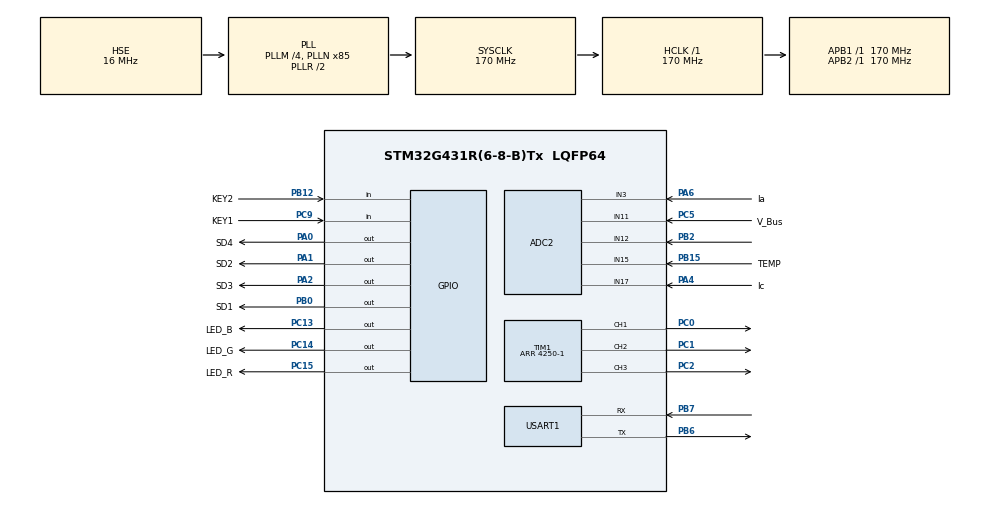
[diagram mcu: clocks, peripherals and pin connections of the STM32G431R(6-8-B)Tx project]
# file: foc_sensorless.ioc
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ADC2.Channel-0\#ChannelRegularConversion=ADC_CHANNEL_11
ADC2.Channel-1\#ChannelRegularConversion=ADC_CHANNEL_12
ADC2.Channel-2\#ChannelRegularConversion=ADC_CHANNEL_15
ADC2.ContinuousConvMode=DISABLE
ADC2.DMAContinuousRequests=ENABLE
ADC2.EnableInjectedConversion=ENABLE
ADC2.ExternalTrigConv=ADC_SOFTWARE_START
ADC2.ExternalTrigInjecConv=ADC_EXTERNALTRIGINJEC_T1_TRGO
ADC2.ExternalTrigInjecConvEdge=ADC_EXTERNALTRIGINJECCONV_EDGE_FALLING
ADC2.InjNumberOfConversion=2
ADC2.InjectedChannel-3\#ChannelInjectedConversion=ADC_CHANNEL_3
ADC2.InjectedChannel-4\#ChannelInjectedConversion=ADC_CHANNEL_17
ADC2.InjectedOffsetNumber-3\#ChannelInjectedConversion=ADC_OFFSET_NONE
ADC2.InjectedOffsetNumber-4\#ChannelInjectedConversion=ADC_OFFSET_NONE
ADC2.InjectedRank-3\#ChannelInjectedConversion=1
ADC2.InjectedRank-4\#ChannelInjectedConversion=2
ADC2.InjectedSamplingTime-3\#ChannelInjectedConversion=ADC_SAMPLETIME_2CYCLES_5
ADC2.InjectedSamplingTime-4\#ChannelInjectedConversion=ADC_SAMPLETIME_2CYCLES_5
ADC2.LowPowerAutoWait=DISABLE
ADC2.NbrOfConversion=3
ADC2.NbrOfConversionFlag=1
ADC2.OffsetNumber-0\#ChannelRegularConversion=ADC_OFFSET_NONE
ADC2.OffsetNumber-1\#ChannelRegularConversion=ADC_OFFSET_NONE
ADC2.OffsetNumber-2\#ChannelRegularConversion=ADC_OFFSET_NONE
ADC2.Rank-0\#ChannelRegularConversion=1
ADC2.Rank-1\#ChannelRegularConversion=2
ADC2.Rank-2\#ChannelRegularConversion=3
ADC2.Rank1_Channel=ADC_CHANNEL_3
ADC2.Rank2_Channel=ADC_CHANNEL_17
ADC2.SamplingTime-0\#ChannelRegularConversion=ADC_SAMPLETIME_92CYCLES_5
ADC2.SamplingTime-1\#ChannelRegularConversion=ADC_SAMPLETIME_92CYCLES_5
ADC2.SamplingTime-2\#ChannelRegularConversion=ADC_SAMPLETIME_92CYCLES_5
Dma.ADC2.0.Direction=DMA_PERIPH_TO_MEMORY
Dma.ADC2.0.EventEnable=DISABLE
Dma.ADC2.0.Instance=DMA1_Channel1
Dma.ADC2.0.MemDataAlignment=DMA_MDATAALIGN_HALFWORD
Dma.ADC2.0.MemInc=DMA_MINC_ENABLE
Dma.ADC2.0.Mode=DMA_CIRCULAR
Dma.ADC2.0.PeriphDataAlignment=DMA_PDATAALIGN_HALFWORD
Dma.ADC2.0.PeriphInc=DMA_PINC_DISABLE
Dma.ADC2.0.Polarity=HAL_DMAMUX_REQ_GEN_RISING
Dma.ADC2.0.Priority=DMA_PRIORITY_LOW
Dma.ADC2.0.RequestNumber=1
Dma.ADC2.0.SignalID=NONE
Dma.ADC2.0.SyncEnable=DISABLE
Dma.ADC2.0.SyncPolarity=HAL_DMAMUX_SYNC_NO_EVENT
Dma.ADC2.0.SyncRequestNumber=1
Dma.ADC2.0.SyncSignalID=NONE
Dma.Request0=ADC2
Mcu.Family=STM32G4
Mcu.Name=STM32G431R(6-8-B)Tx
Mcu.Package=LQFP64
NVIC.ADC1_2_IRQn=true\:0\:0\:false\:false\:true\:true\:true\:true
NVIC.DMA1_Channel1_IRQn=true\:0\:0\:false\:false\:true\:false\:true\:true
NVIC.PriorityGroup=NVIC_PRIORITYGROUP_4
NVIC.TIM1_UP_TIM16_IRQn=true\:0\:0\:false\:false\:true\:true\:true\:true
NVIC.TIM2_IRQn=true\:0\:0\:false\:false\:true\:true\:true\:true
NVIC.USART1_IRQn=true\:0\:0\:false\:false\:true\:true\:true\:true
PA0.GPIO_Label=SD4
PA0.Signal=GPIO_Output
PA1.GPIO_Label=SD2
PA1.Signal=GPIO_Output
PA13.Mode=Serial_Wire
PA13.Signal=SYS_JTMS-SWDIO
PA14.Mode=Serial_Wire
PA14.Signal=SYS_JTCK-SWCLK
PA2.GPIO_Label=SD3
PA2.Signal=GPIO_Output
PA4.GPIO_Label=Ic
PA4.Mode=IN17-Single-Ended
PA4.Signal=ADC2_IN17
PA6.GPIO_Label=Ia
PA6.Mode=IN3-Single-Ended
PA6.Signal=ADC2_IN3
PB0.GPIO_Label=SD1
PB0.Signal=GPIO_Output
PB12.GPIO_Label=KEY2
PB12.GPIO_PuPd=GPIO_PULLUP
PB12.Signal=GPIO_Input
PB15.GPIO_Label=TEMP
PB15.Mode=IN15-Single-Ended
PB15.Signal=ADC2_IN15
PB2.Mode=IN12-Single-Ended
PB2.Signal=ADC2_IN12
PB6.Mode=Asynchronous
PB6.Signal=USART1_TX
PB7.Mode=Asynchronous
PB7.Signal=USART1_RX
PC0.Signal=S_TIM1_CH1
PC1.Signal=S_TIM1_CH2
PC13.GPIO_Label=LED_B
PC13.Signal=GPIO_Output
PC14-OSC32_IN.GPIO_Label=LED_G
PC14-OSC32_IN.Signal=GPIO_Output
PC15-OSC32_OUT.GPIO_Label=LED_R
PC15-OSC32_OUT.Signal=GPIO_Output
PC2.Signal=S_TIM1_CH3
PC5.GPIO_Label=V_Bus
PC5.Mode=IN11-Single-Ended
PC5.Signal=ADC2_IN11
PC9.GPIO_Label=KEY1
PC9.GPIO_PuPd=GPIO_PULLUP
PC9.Signal=GPIO_Input
PF0-OSC_IN.Mode=HSE-External-Oscillator
PF0-OSC_IN.Signal=RCC_OSC_IN
PF1-OSC_OUT.Mode=HSE-External-Oscillator
PF1-OSC_OUT.Signal=RCC_OSC_OUT
ProjectManager.HeapSize=0x200
ProjectManager.StackSize=0x400
ProjectManager.TargetToolchain=MDK-ARM V5.32
RCC.ADC12Freq_Value=170000000
RCC.AHBFreq_Value=170000000
RCC.APB1Freq_Value=170000000
RCC.APB1TimFreq_Value=170000000
RCC.APB2Freq_Value=170000000
RCC.APB2TimFreq_Value=170000000
RCC.CortexFreq_Value=170000000
RCC.EXTERNAL_CLOCK_VALUE=12288000
RCC.HCLKFreq_Value=170000000
RCC.HSE_VALUE=16000000
RCC.HSI48_VALUE=48000000
RCC.HSI_VALUE=16000000
RCC.LSE_VALUE=32768
RCC.PLLM=RCC_PLLM_DIV4
RCC.PLLN=85
RCC.PLLSourceVirtual=RCC_PLLSOURCE_HSE
RCC.SYSCLKFreq_VALUE=170000000
RCC.SYSCLKSource=RCC_SYSCLKSOURCE_PLLCLK
RCC.USBFreq_Value=170000000
RCC.VCOOutputFreq_Value=340000000
SH.S_TIM1_CH1.0=TIM1_CH1,PWM Generation1 CH1
SH.S_TIM1_CH2.0=TIM1_CH2,PWM Generation2 CH2
SH.S_TIM1_CH3.0=TIM1_CH3,PWM Generation3 CH3
TIM1.AutoReloadPreload=TIM_AUTORELOAD_PRELOAD_ENABLE
TIM1.Channel-PWM\ Generation1\ CH1=TIM_CHANNEL_1
TIM1.Channel-PWM\ Generation2\ CH2=TIM_CHANNEL_2
TIM1.Channel-PWM\ Generation3\ CH3=TIM_CHANNEL_3
TIM1.CounterMode=TIM_COUNTERMODE_CENTERALIGNED1
TIM1.OCMode_PWM-PWM\ Generation1\ CH1=TIM_OCMODE_PWM2
TIM1.OCMode_PWM-PWM\ Generation2\ CH2=TIM_OCMODE_PWM2
TIM1.OCMode_PWM-PWM\ Generation3\ CH3=TIM_OCMODE_PWM2
TIM1.PeriodNoDither=4250-1
TIM1.RepetitionCounter=0
TIM1.TIM_MasterOutputTrigger=TIM_TRGO_UPDATE
TIM2.AutoReloadPreload=TIM_AUTORELOAD_PRELOAD_ENABLE
TIM2.PeriodNoDither=10000-1
TIM2.Prescaler=170-1
USART1.VirtualMode-Asynchronous=VM_ASYNC
VP_SYS_VS_DBSignals.Mode=DisableDeadBatterySignals
VP_TIM1_VS_ClockSourceINT.Mode=Internal
VP_TIM2_VS_ClockSourceINT.Mode=Internal
board=custom

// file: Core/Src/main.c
/* USER CODE BEGIN Header */
/**
 ******************************************************************************
 * @file           : main.c
 * @brief          : Main program body
 ******************************************************************************
 * @attention
 *
 * Copyright (c) 2026 STMicroelectronics.
 * All rights reserved.
 *
 * This software is licensed under terms that can be found in the LICENSE file
 * in the root directory of this software component.
 * If no LICENSE file comes with this software, it is provided AS-IS.
 *
 ******************************************************************************
 */
/* USER CODE END Header */
#include "main.h"
#include "adc.h"
#include "dma.h"
#include "tim.h"
#include "usart.h"
#include "gpio.h"

/* USER CODE BEGIN Includes */
#include "globalControl.h"
#include "driver.h"
/* USER CODE END Includes */

void SystemClock_Config(void);

int main(void)
{

  /* MCU Configuration--------------------------------------------------------*/

  /* Reset of all peripherals, Initializes the Flash interface and the Systick. */
  HAL_Init();

  /* Configure the system clock */
  SystemClock_Config();

  /* Initialize all configured peripherals */
  MX_GPIO_Init();
  MX_DMA_Init();
  MX_TIM1_Init();
  MX_USART1_UART_Init();
  MX_ADC2_Init();
  MX_TIM2_Init();
  /* USER CODE BEGIN 2 */
    Motor_t *motor = GetMotorStruct();
    Temperature_t *temp = GetTempStruct();

    TemperatureInit(temp);
    MotorParaInit(motor);
    FuncRegister();
  /* USER CODE END 2 */

  /* Infinite loop */
  /* USER CODE BEGIN WHILE */
  while (1)
  {
      TxMotorData(motor, temp);
    /* USER CODE END WHILE */

  }
}

void SystemClock_Config(void)
{
  RCC_OscInitTypeDef RCC_OscInitStruct = {0};
  RCC_ClkInitTypeDef RCC_ClkInitStruct = {0};

  /** Configure the main internal regulator output voltage
  */
  HAL_PWREx_ControlVoltageScaling(PWR_REGULATOR_VOLTAGE_SCALE1_BOOST);

  /** Initializes the RCC Oscillators according to the specified parameters
  * in the RCC_OscInitTypeDef structure.
  */
  RCC_OscInitStruct.OscillatorType = RCC_OSCILLATORTYPE_HSE;
  RCC_OscInitStruct.HSEState = RCC_HSE_ON;
  RCC_OscInitStruct.PLL.PLLState = RCC_PLL_ON;
  RCC_OscInitStruct.PLL.PLLSource = RCC_PLLSOURCE_HSE;
  RCC_OscInitStruct.PLL.PLLM = RCC_PLLM_DIV4;
  RCC_OscInitStruct.PLL.PLLN = 85;
  RCC_OscInitStruct.PLL.PLLP = RCC_PLLP_DIV2;
  RCC_OscInitStruct.PLL.PLLQ = RCC_PLLQ_DIV2;
  RCC_OscInitStruct.PLL.PLLR = RCC_PLLR_DIV2;
  if (HAL_RCC_OscConfig(&RCC_OscInitStruct) != HAL_OK)
  {
    Error_Handler();
  }

  /** Initializes the CPU, AHB and APB buses clocks
  */
  RCC_ClkInitStruct.ClockType = RCC_CLOCKTYPE_HCLK|RCC_CLOCKTYPE_SYSCLK
                              |RCC_CLOCKTYPE_PCLK1|RCC_CLOCKTYPE_PCLK2;
  RCC_ClkInitStruct.SYSCLKSource = RCC_SYSCLKSOURCE_PLLCLK;
  RCC_ClkInitStruct.AHBCLKDivider = RCC_SYSCLK_DIV1;
  RCC_ClkInitStruct.APB1CLKDivider = RCC_HCLK_DIV1;
  RCC_ClkInitStruct.APB2CLKDivider = RCC_HCLK_DIV1;

  if (HAL_RCC_ClockConfig(&RCC_ClkInitStruct, FLASH_LATENCY_4) != HAL_OK)
  {
    Error_Handler();
  }
}

void Error_Handler(void)
{
  __disable_irq();
  while (1)
  {
  }
}
